# STM32L083xx register map
File version: 1.0
Registers are 32-bit, read-write, reset 0x0 unless marked. A register's access mark holds for its fields unless they carry their own. Offsets are from the block's base; [hi:lo] are bit positions; {n}, {i} and the like mark numbered series; 'fields as' and 'values as' point back to an identical list.

## SYSCFG — SysTem Configuration
Base 0x40010000
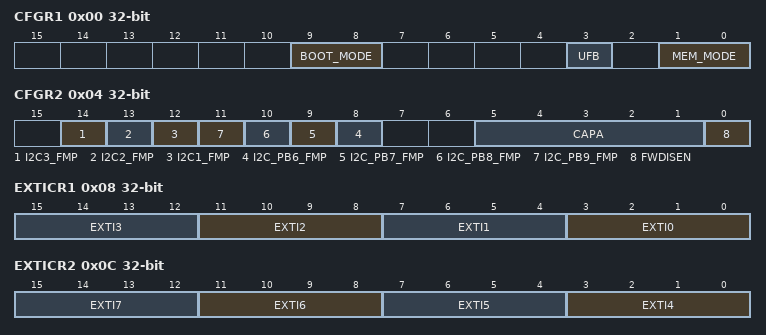
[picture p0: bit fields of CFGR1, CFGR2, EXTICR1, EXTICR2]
0x00 CFGR1 — SYSCFG configuration register 1
  [9:8] BOOT_MODE — SYSCFG_Boot mode Config
    0=FLASH (Main Flash memory boot mode); 1=SYSTEMFLASH (System Flash memory boot mode); 3=SRAM (SRAM boot mode)
  [3] UFB — User bank swapping
    0=BANK1; 1=BANK2
  [1:0] MEM_MODE — SYSCFG_Memory Remap Config
    0=FLASH (Main Flash memory mapped at 0x00000000); 1=SYSTEMFLASH (System Flash memory mapped at 0x00000000); 3=SRAM (SRAM mapped at 0x00000000)
0x04 CFGR2 — SYSCFG configuration register 2
  [14] I2C3_FMP — I2C3 Fast mode plus
  [13] I2C2_FMP — I2C2 Fast mode plus
  [12] I2C1_FMP — I2C1 Fast mode plus
  [n+2] I2C_PB{n}_FMP (n=6..9) — I2C PB{n} Fast mode plus
  [5:1] CAPA — Connection of internal Vlcd rail to external capacitors
    2=VLCD1_PB12 (Connect PB12 pin to LCD_VLCD1 rails supply voltage); 8=VLCD1_PE11 (Connect PE11 pin to LCD_VLCD1 rails supply voltage); 1=VLCD2_PB2 (Connect PB2 pin to LCD_VLCD2 rails supply voltage); 4=VLCD3_PB0 (Connect PB0 pin to LCD_VLCD3 rails supply voltage); 16=VLCD3_PE12 (Connect PE12 pin to LCD_VLCD3 rails supply voltage)
  [0] FWDISEN — Firewall disable bit
0x08 EXTICR1 — SYSCFG external interrupt configuration register
  [4n+3:4n] EXTI{n} (n=0..3) — EXTI {n} configuration
0x0C EXTICR2 — SYSCFG external interrupt configuration register
  [4n-13:4n-16] EXTI{n} (n=4..7) — EXTI {n} configuration
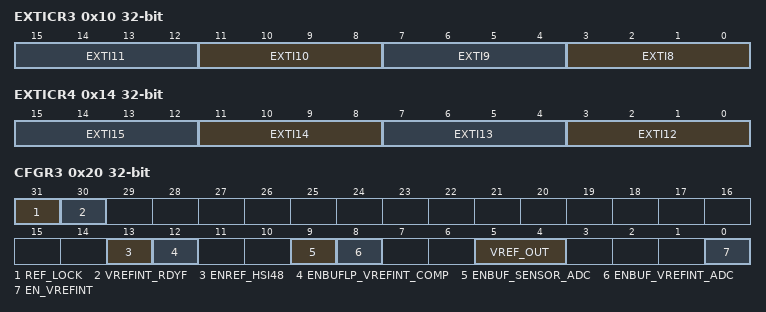
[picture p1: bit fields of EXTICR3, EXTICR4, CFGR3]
0x10 EXTICR3 — SYSCFG external interrupt configuration register
  [4n-29:4n-32] EXTI{n} (n=8..11) — EXTI {n} configuration
0x14 EXTICR4 — SYSCFG external interrupt configuration register
  [4n-45:4n-48] EXTI{n} (n=12..15) — EXTI {n} configuration
0x20 CFGR3 — SYSCFG configuration register 3
  [31] REF_LOCK — CFGR3 lock bit
  [30] VREFINT_RDYF — VREFINT ready flag
  [13] ENREF_HSI48 — VREFINT reference or 48 MHz RC oscillator enable bit
  [12] ENBUFLP_VREFINT_COMP — VREFINT reference for comparator 2 enable bit
  [9] ENBUF_SENSOR_ADC — Sensor reference for ADC enable bit
  [8] ENBUF_VREFINT_ADC — VREFINT reference for ADC enable bit
  [5:4] VREF_OUT — Verf_ADC connection bit
    0=NONE (No pad connected to VREFINT_ADC); 1=IO1 (PB0 connected to VREFINT_ADC); 2=IO2 (PB1 connected to VREFINT_ADC); 3=IO1_IO2 (PB0 and PB1 connected to VREFINT_ADC)
  [0] EN_VREFINT — Vref Enable bit

## COMP1 — Comparator
Base 0x40010018
Same registers: COMP2 0x4001001C
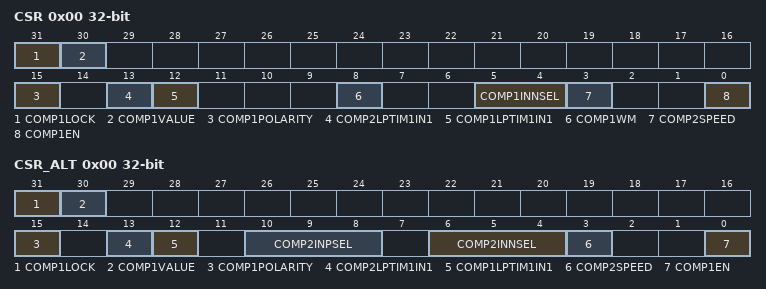
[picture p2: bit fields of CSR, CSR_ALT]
0x00 CSR — COMP comparator control and status register
  [31] COMP1LOCK
  [30] COMP1VALUE — COMP1 output level
  [15] COMP1POLARITY — COMP1 output polarity
  [13] COMP2LPTIM1IN1 — COMP2 LPTIM1 IN1 connection
  [12] COMP1LPTIM1IN1 — COMP1 LPTIM1 IN1 connection
  [8] COMP1WM — Comparators window mode enable
    0=DISABLE (Window mode disable: Comparators 1 and 2 are independent); 1=COMP1_INPUT_PLUS_COMMON (Window mode enable: Comparators instances pair COMP1 and COMP2 have their input plus connected together. The common input is COMP1 input plus (COMP2 input plus is no more accessible).)
  [5:4] COMP1INNSEL — COMP1 inverting input select
  [3] COMP2SPEED — COMP2 power mode
    1=MEDIUMSPEED (COMP power mode to fast speed (specific to COMP instance: COMP2)); 0=ULTRALOWPOWER (COMP power mode to low speed (specific to COMP instance: COMP2))
  [0] COMP1EN — COMP1 enable
0x00 CSR_ALT (alternate view of CSR) — COMP comparator control and status register
  [31] COMP1LOCK
  [30] COMP1VALUE — COMP1 output level
  [15] COMP1POLARITY — COMP1 output polarity
  [13] COMP2LPTIM1IN1 — COMP2 LPTIM1 IN1 connection
  [12] COMP1LPTIM1IN1 — COMP1 LPTIM1 IN1 connection
  [10:8] COMP2INPSEL — COMPx non inverting input select
    0=IO1 (Comparator input plus connected to IO1 (pin PA1 for COMP1, pin PA3 for COMP2)); 1=IO2 (Comparator input plus connected to IO2 (pin PB4 for COMP2) (specific to COMP instance: COMP2)); 2=IO3 (Comparator input plus connected to IO3 (pin PA5 for COMP2) (specific to COMP instance: COMP2)); 3=IO4 (Comparator input plus connected to IO4 (pin PB6 for COMP2) (specific to COMP instance: COMP2)); 4=IO5 (Comparator input plus connected to IO5 (pin PB7 for COMP2) (specific to COMP instance: COMP2))
  [6:4] COMP2INNSEL — COMP2 inverting input select
    0=VREFINT (Comparator input minus connected to VrefInt (specifity of COMP2 related to path to enable via SYSCFG: refer to comment in function @ref LL_COMP_SetInputMinus() )); 1=IO1 (Comparator input minus connected to IO1 (pin PA0 for COMP1, pin PA2 for COMP2)); 2=DAC1_CH1 (Comparator input minus connected to DAC1 channel 1 (DAC_OUT1)); 3=DAC1_CH2 (Comparator input minus connected to DAC1 channel 2 (DAC_OUT2)); 4=MINUS_1_4VREFINT (Comparator input minus connected to 1/4 VrefInt (specifity of COMP2 related to path to enable via SYSCFG: refer to comment in function @ref LL_COMP_SetInputMinus() ) (specific to COMP instance: COMP2)); 5=MINUS_1_2VREFINT (Comparator input minus connected to 1/2 VrefInt (specifity of COMP2 related to path to enable via SYSCFG: refer to comment in function @ref LL_COMP_SetInputMinus() ) (specific to COMP instance: COMP2)); 6=MINUS_3_4VREFINT (Comparator input minus connected to 3/4 VrefInt (specifity of COMP2 related to path to enable via SYSCFG: refer to comment in function @ref LL_COMP_SetInputMinus() ) (specific to COMP instance: COMP2)); 7=IO2 (Comparator input minus connected to IO2 (pin PB3 for COMP2) (specific to COMP instance: COMP2))
  [3] COMP2SPEED — COMP2 power mode
    values as CSR.COMP2SPEED
  [0] COMP1EN — COMP1 enable
